# PCIE0_CORE_DBN_CFG_PCIE_CORE register map
Vendor: Texas Instruments
Registers are 32-bit, read-write, reset 0x0 unless marked. A register's access mark holds for its fields unless they carry their own. Offsets are as the file gives them; [hi:lo] are bit positions; {n}, {i} and the like mark numbered series.

## PCIE0_CORE_DBN_CFG_PCIE_CORE (part 3 of 6)
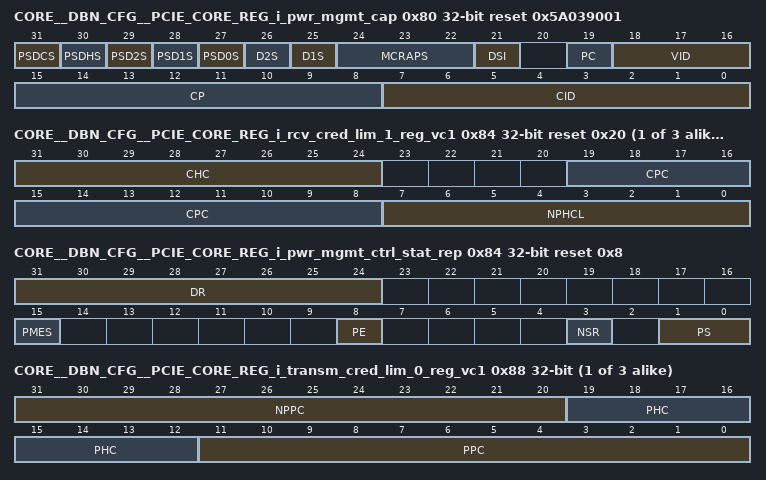
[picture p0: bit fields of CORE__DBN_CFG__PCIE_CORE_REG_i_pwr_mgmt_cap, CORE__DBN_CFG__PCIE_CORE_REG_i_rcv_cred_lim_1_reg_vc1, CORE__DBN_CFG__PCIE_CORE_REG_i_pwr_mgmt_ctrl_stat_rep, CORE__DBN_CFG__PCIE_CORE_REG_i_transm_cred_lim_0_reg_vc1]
0x80 CORE__DBN_CFG__PCIE_CORE_REG_i_pwr_mgmt_cap ro reset 0x5A039001
  [31] PSDCS — Indicates whether the Function is capable of sending PME messages when in the D3cold state. This field can be written from the APB bus by setting [21] bit high of the pcie_mgmt_APB_ADDR during a local management register write.
  [30] PSDHS — Indicates whether the Function is capable of sending PME messages when in the D3hot state. This field can be written from the APB bus by setting [21] bit high of the pcie_mgmt_APB_ADDR during a local management register write.
  [29] PSD2S — Indicates whether the Function is capable of sending PME messages when in the D2 state. This bit is hardwired to 0 because D2 state is not supported.
  [28] PSD1S — Indicates whether the Function is capable of sending PME messages when in the D1 state. This bit is set to 1 by default, but can be modified from the local management bus by writing into Function 0. All other Functions assume the value set in Function 0s Power Management Capabilities Register.
  [27] PSD0S — Indicates whether the Function is capable of sending PME messages when in the D0 state. This field can be written from the APB bus by setting [21] bit high of the pcie_mgmt_APB_ADDR during a local management register write.
  [26] D2S — Set if the Function supports the D2 power state. Currently hardwired to 0.
  [25] D1S — Set if the Function supports the D1 power state. This field can be written from the APB bus by setting [21] bit high of the pcie_mgmt_APB_ADDR during a local management register write.
  [24:22] MCRAPS — Specifies the maximum current drawn by the device from the aux power source in the D3cold state. This field is not implemented in devices not supporting PME notification when in the D3cold state, and is therefore hardwired to 0.
  [21] DSI — This bit, when set, indicates that the device requires additional configuration steps beyond setting up its PCI configuration space, to bring it to the D0 active state from the D0 uninitialized state. This bit is hardwired to 0.
  [19] PC — Not applicable to PCI Express. This bit is hardwired to 0.
  [18:16] VID — Indicates the version of the PCI Bus Power Management Specifications that the Function implements. This field is set by default to 011 [Version 1.2]. This field can be written from the APB bus by setting [21] bit high of the pcie_mgmt_APB_ADDR during a local management register write.
  [15:8] CP — Contains pointer to the next PCI Capability Structure. The Controller sets it to the value defined in the RTL file reg_defaults.h. This field can be written from the APB bus by setting [21] bit high of the pcie_mgmt_APB_ADDR during a local management register write.
  [7:0] CID — Identifies that the capability structure is for Power Management. This field is set by default to 01 hex. This field can be written from the APB bus by setting [21] bit high of the pcie_mgmt_APB_ADDR during a local management register write.
{0x74+0x10*i} CORE__DBN_CFG__PCIE_CORE_REG_i_rcv_cred_lim_1_reg_vc{i} reset 0x20 (i=1..3)
  [31:24] CHC — Completion header credit limit advertised by the Controller for VC {i} [in number of packets]. This field is in units of 1, 4 or 16 Packet Headers based on the Local Posted Header Credit Scale for VC {i}. 00b => [units of 1 Packet Header] 01b => [units of 1 Packet Header] 10b => [units of 4 Packet Headers] 11b => [units of 16 Packet Headers] Note: When Scaled FLow Control is Activated, the programmed credit value is advertised in the InitFC DLLPs. Else, the programmed credit value is internally normalized to units of [1 Packet Header] and then advertised in the InitFC DLLPs. Note: Packet Header represents one maximum-size TLP Header + TLP Digest + maximum number of EndEnd TLP Prefixes permitted in a TLP. Caution: The programmed Header and Payload credit values must not exceed the actual size of the Receive Buffer.
  [19:8] CPC — Completion payload credit limit advertised by the Controller for VC {i} . This field is in units of 4 DWords, 16 DWords or 64 DWords based on the Local Posted Payload Credit Scale for VC {i}. 00b => [units of 4 DWords] 01b => [units of 4 DWords] 10b => [units of 16 DWords] 11b => [units of 64 DWords] Note: When Scaled FLow Control is Activated, the programmed credit value is advertised in the InitFC DLLPs. Else, the programmed credit value is internally normalized to units of 4 DW and then advertised in the InitFC DLLPs. Caution: The programmed Header and Payload credit values must not exceed the actual size of the Receive Buffer.
  [7:0] NPHCL — Non-Posted header credit limit advertised by the Controller for VC {i} [in number of packets]. This field is in units of 1, 4 or 16 Packet Headers based on the Local Posted Header Credit Scale for VC {i}. 00b => [units of 1 Packet Header] 01b => [units of 1 Packet Header] 10b => [units of 4 Packet Headers] 11b => [units of 16 Packet Headers] Note: When Scaled FLow Control is Activated, the programmed credit value is advertised in the InitFC DLLPs. Else, the programmed credit value is internally normalized to units of [1 Packet Header] and then advertised in the InitFC DLLPs. Note: Packet Header represents one maximum-size TLP Header + TLP Digest + maximum number of EndEnd TLP Prefixes permitted in a TLP. Caution: The programmed Header and Payload credit values must not exceed the actual size of the Receive Buffer.
0x84 CORE__DBN_CFG__PCIE_CORE_REG_i_pwr_mgmt_ctrl_stat_rep access not given reset 0x8
  [31:24] DR ro — This optional register is not implemented in the Cadence PCIe Controller. This field is hardwired to 0.
  [15] PMES — This field can be written from the APB bus by setting [21] bit high of the pcie_mgmt_APB_ADDR during a local management register write.. (access R/W1TC)
  [8] PE rw — This bit can be set or cleared from the local management APB bus, by writing a 1 or 0, respectively.
  [3] NSR ro — This bit is set to 1 by default. This field can be written from the APB bus by setting [21] bit high of the pcie_mgmt_APB_ADDR during a local management register write.
  [1:0] PS rw — This field can also be read or written from the local management APBbus.
{0x78+0x10*i} CORE__DBN_CFG__PCIE_CORE_REG_i_transm_cred_lim_0_reg_vc{i} ro (i=1..3)
  [31:20] NPPC — Non-Posted payload credit limit received by the Controller for Link 0 . This field is in units of 4 DWords, 16 DWords or 64 DWords based on the Remote Posted Payload Credit Scale for VC {i}. 00b => [units of 4 DWords] 01b => [units of 4 DWords] 10b => [units of 16 DWords] 11b => [units of 64 DWords]
  [19:12] PHC — Posted header credit limit received by the Controller for this link . This field is in units of 1, 4 or 16 Packet Headers based on the Remote Posted Header Credit Scale for VC {i}. 00b => [units of 1 Packet Header] 01b => [units of 1 Packet Header] 10b => [units of 4 Packet Headers] 11b => [units of 16 Packet Headers] Note: Packet Header represents one maximum-size TLP Header + TLP Digest + maximum number of EndEnd TLP Prefixes permitted in a TLP.
  [11:0] PPC — Posted payload credit limit received by the Controller for this link . This field is in units of 4 DWords, 16 DWords or 64 DWords based on the Remote Posted Payload Credit Scale for VC {i}. 00b => [units of 4 DWords] 01b => [units of 4 DWords] 10b => [units of 16 DWords] 11b => [units of 64 DWords]
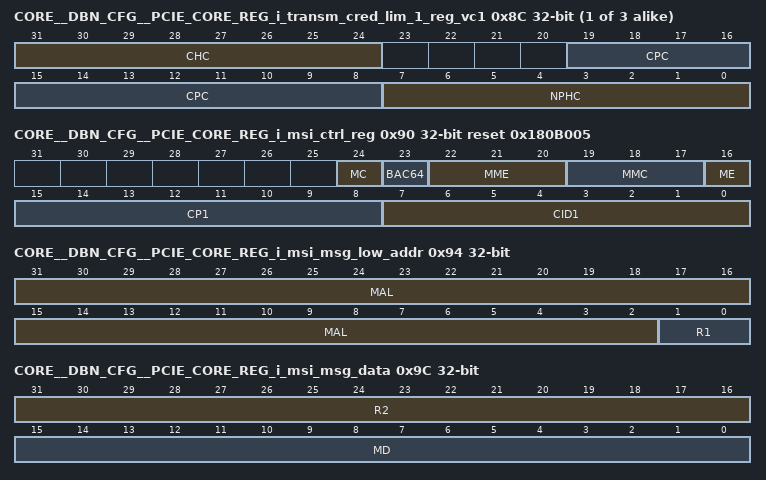
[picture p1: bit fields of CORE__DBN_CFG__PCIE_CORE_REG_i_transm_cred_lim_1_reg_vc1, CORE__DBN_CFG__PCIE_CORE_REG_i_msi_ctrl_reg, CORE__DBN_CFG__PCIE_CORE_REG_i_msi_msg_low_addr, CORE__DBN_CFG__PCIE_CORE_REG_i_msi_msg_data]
{0x7C+0x10*i} CORE__DBN_CFG__PCIE_CORE_REG_i_transm_cred_lim_1_reg_vc{i} ro (i=1..3)
  [31:24] CHC — Completion header credit limit received by the Controller for VC {i} . This field is in units of 1, 4 or 16 Packet Headers based on the Remote Posted Header Credit Scale for VC {i}. 00b => [units of 1 Packet Header] 01b => [units of 1 Packet Header] 10b => [units of 4 Packet Headers] 11b => [units of 16 Packet Headers] Note: Packet Header represents one maximum-size TLP Header + TLP Digest + maximum number of EndEnd TLP Prefixes permitted in a TLP.
  [19:8] CPC — Completion payload credit limit received by the Controller for VC {i} . This field is in units of 4 DWords, 16 DWords or 64 DWords based on the Remote Posted Payload Credit Scale for VC {i}. 00b => [units of 4 DWords] 01b => [units of 4 DWords] 10b => [units of 16 DWords] 11b => [units of 64 DWords]
  [7:0] NPHC — Non-Posted header credit limit received by the Controller for VC {i} . This field is in units of 1, 4 or 16 Packet Headers based on the Remote Posted Header Credit Scale for VC {i}. 00b => [units of 1 Packet Header] 01b => [units of 1 Packet Header] 10b => [units of 4 Packet Headers] 11b => [units of 16 Packet Headers] Note: Packet Header represents one maximum-size TLP Header + TLP Digest + maximum number of EndEnd TLP Prefixes permitted in a TLP.
0x90 CORE__DBN_CFG__PCIE_CORE_REG_i_msi_ctrl_reg access per field reset 0x180B005
  [24] MC ro — can be modified using localmanagement interface
  [23] BAC64 ro — Set to 1 to indicate that the device is capable of generating 64-bit addresses for MSI messages.Can be modified using local management interface
  [22:20] MME rw — Encodes the number of distinct messages that the Controller is programmed to generate for this Function [000 = 1, 001 = 2, 010 = 4, 011 = 8, 100 = 16, 101 = 32]. This setting must be based on the number of interrupt inputs of the Controller that are actually used by this Function. This field can be written from the local management bus.
  [19:17] MMC ro — Encodes the number of distinct messages that the Controller is capable of generating for this Function [000 = 1, 001 = 2, 010 = 4, 011 = 8, 100 = 16, 101 = 32]. Thus, this field defines the number of the interrupt vectors for this Function. The Controller allows up to 32 distinct messages, but the setting of this field must be based on the number of interrupt inputs of the Controller that are actually used by the client. For example, if the client logic uses 8 of the 32 distinct MSI interrupt inputs of the Controller for this Function, then the value of this field must be set to 011. This field can be written from the local management bus. Please see the define den_db_Fx_MSI_MULTIPLE_MSG_CAPABLE values [where x is the function number] for default values of each function in the reg_defaults.v files.
  [16] ME rw — Set by the configuration program to enable the MSI feature. This field can also be written from the local management bus.
  [15:8] CP1 ro — Pointer to the next PCI Capability Structure. This can be modified from the local management bus. This field can be written from the local management bus.
  [7:0] CID1 ro — Specifies that the capability structure is for MSI. Hardwired to 05 hex.
0x94 CORE__DBN_CFG__PCIE_CORE_REG_i_msi_msg_low_addr access per field
  [31:2] MAL rw — Lower bits of the address to be used in MSI messages. This field can also be written from the local management bus.
  [1:0] R1 ro — The two lower bits of the address are hardwired to 0 to align the address on a double-word boundary.
0x98 CORE__DBN_CFG__PCIE_CORE_REG_i_msi_msg_hi_addr
  [31:0] MAH — Contains bits 63:32 of the 64-bit address to be used in MSI Messages. A value of 0 specifies that 32-bit addresses are to be used in the messages. This field can also be written from the local management bus.
0x9C CORE__DBN_CFG__PCIE_CORE_REG_i_msi_msg_data access per field
  [31:16] R2 ro — Hardwired to 0
  [15:0] MD rw — Message data to be used for this Function. This field can also be written from the local management bus.
0xA0 CORE__DBN_CFG__PCIE_CORE_REG_i_msi_mask
  [0] MM — Mask bits for MSI interrupts. The Multiple Message Capable field of the MSI Control Register specifies the number of distinct interrupts for the Function, which determines the number of valid mask bits.
0xA4 CORE__DBN_CFG__PCIE_CORE_REG_i_msi_pending_bits ro
  [0] MP — Pending bits for MSI interrupts. This field can be written from the APB interface to refelct the current pending status.
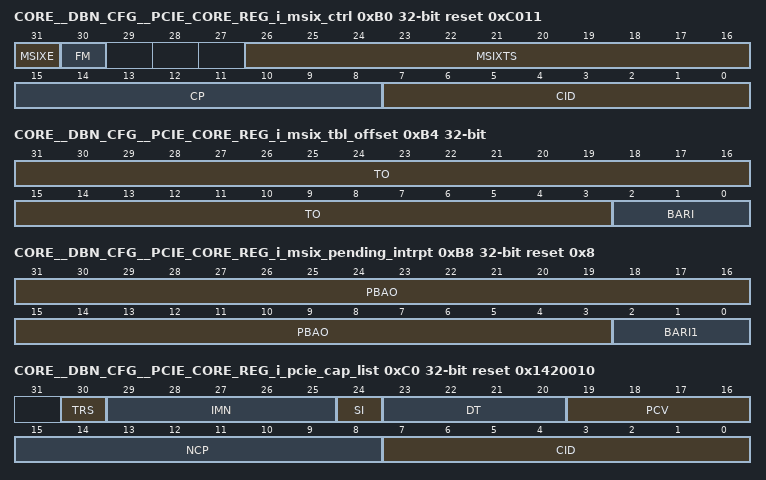
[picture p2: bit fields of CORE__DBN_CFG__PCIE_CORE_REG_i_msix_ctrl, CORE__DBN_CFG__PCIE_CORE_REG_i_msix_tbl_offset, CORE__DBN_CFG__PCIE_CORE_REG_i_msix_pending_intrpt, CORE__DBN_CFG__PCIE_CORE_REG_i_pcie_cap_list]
0xB0 CORE__DBN_CFG__PCIE_CORE_REG_i_msix_ctrl access per field reset 0xC011
  [31] MSIXE rw — Set by the configuration program to enable the MSI-X feature. This field can also be written from the local management bus.
  [30] FM rw — This bit serves as a global mask to all the interrupt conditions associated with this Function. When this bit is set, the Controller will not send out MSI-X messages from this Function. This field can also be written from the local management bus.
  [26:16] MSIXTS ro — Specifies the size of the MSI-X Table, that is, the number of interrupt vectors defined for the Function. The programmed value is 1 minus the size of the table [that is, this field is set to 0 if the table size is 1.]. It can be re-written independently for each Function from the local management bus. Please see the define den_db_Fx_MSIX_TABLE_SIZE values [where x is the function number] for default values of each function in the reg_defaults.v files.
  [15:8] CP ro — Contains pointer to the next PCI Capability Structure. This is set to point to the PCI Express Capability Structure at 30 hex. This can be rewritten independently for each Function from the local management bus.
  [7:0] CID ro — Identifies that the capability structure is for MSI-X. This field is set by default to 11 hex. It can be rewritten independently for each Function from the local management bus.
0xB4 CORE__DBN_CFG__PCIE_CORE_REG_i_msix_tbl_offset ro
  [31:3] TO — Offset of the memory address where the MSI-X Table is located, relative to the selected BAR. The three least significant bits of the address are omitted, as the addresses are QWORD aligned. Please see the define den_db_Fx_MSIX_TABLE_OFFSET values [where x is the function number] for default values of each function in the reg_defaults.v files.
  [2:0] BARI — Identifies the BAR corresponding to the memory address range where the MSI-X Table is located [000 = BAR 0, 001 = BAR 1, ... , 101 = BAR 5]. Please see the define den_db_Fx_MSIX_TABLE_BIR values [where x is the function number] for default values of each function in the reg_defaults.v files.
0xB8 CORE__DBN_CFG__PCIE_CORE_REG_i_msix_pending_intrpt ro reset 0x8
  [31:3] PBAO — Offset of the memory address where the PBA is located, relative to the selected BAR. The three least significant bits of the address are omitted, as the addresses are QWORD aligned. Please see the define den_db_Fx_MSIX_PBA_OFFSET values [where x is the function number] for default values of each function in the reg_defaults.v files.
  [2:0] BARI1 — Identifies the BAR corresponding to the memory address range where the PBA Structure is located [000 = BAR 0, 001 = BAR 1, ... , 101 = BAR 5]. The value programmed must be the same as the BAR Indicator configured in the MSI-X Table Offset Register.Identifies the BAR corresponding to the memory address range where the PBA Structure is located [000 = BAR 0, 001 = BAR 1, ... , 101 = BAR 5]. The value programmed must be the same as the BAR Indicator configured in the MSI-X Table Offset Register. Please see the define den_db_Fx_MSIX_PBA_BIR values [where x is the function number] for default values of each function in the reg_defaults.v files.
0xC0 CORE__DBN_CFG__PCIE_CORE_REG_i_pcie_cap_list ro reset 0x1420010
  [30] TRS — When set to 1, this bit indicates that the device supports routing of Trusted Configuration Requests. Not valid for Endpoints. Hardwired to 0.
  [29:25] IMN — Identifies the MSI or MSI-X interrupt vector for the interrupt message generated corresponding to the status bits in the Slot Status Register, Root Status Register, or this capability structure. This field must be defined based on the chosen interrupt mode - MSI or MSI-X. This field is hardwired to 0.
  [24] SI — When Set, this bit indicates that the Link associated with this Port is connected to a slot
  [23:20] DT — Indicates the type of device implementing this Function. This field is hardwired to 4 in the RP mode.
  [19:16] PCV — Identifies the version number of the capability structure. This field is set to 2 by default to indicate that the Controller is compatible to PCI Express Base Specification Revision 3.0. Can be modified using local management interface after asserting input signal MGMT_TYPE1_CONFIG_REG_ACCESS high.
  [15:8] NCP — Points to the next PCI capability structure. Set to 0 because this is the last capability structure.
  [7:0] CID — Specifies Capability ID assigned by PCI SIG for this structure. This field is hardwired to 10 hex.
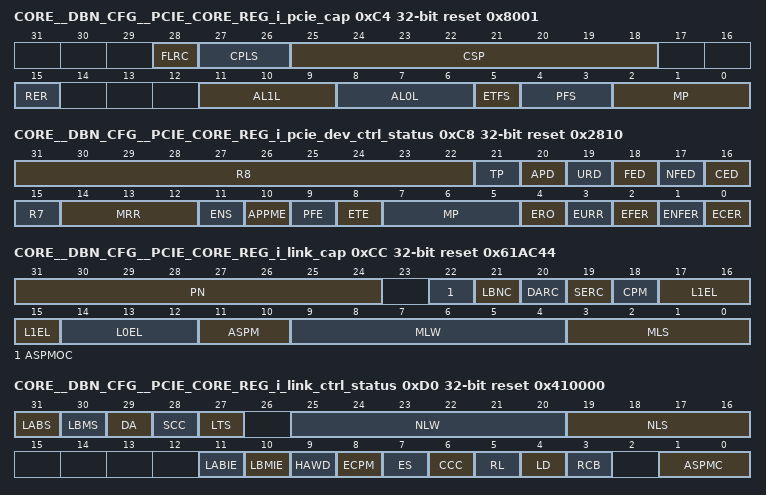
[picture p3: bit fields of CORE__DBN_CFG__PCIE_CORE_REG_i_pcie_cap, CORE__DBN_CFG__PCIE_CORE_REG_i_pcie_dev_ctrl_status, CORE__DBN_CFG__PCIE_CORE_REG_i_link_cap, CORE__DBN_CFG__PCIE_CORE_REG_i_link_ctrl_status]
0xC4 CORE__DBN_CFG__PCIE_CORE_REG_i_pcie_cap ro reset 0x8001
  [28] FLRC — A value of 1b indicates the Function supports the optional Function Level Reset mechanism
  [27:26] CPLS — Specifies the scale used by Slot Power Limit Value. This field can be written from the APB bus by setting [21] bit high of the pcie_mgmt_APB_ADDR during a local management register write. .
  [25:18] CSP — Specifies upper limit on power supplied by slot. This field can be written from the APB bus by setting [21] bit high of the pcie_mgmt_APB_ADDR during a local management register write. .
  [15] RER — Enables role-based errer reporting. This field can be written from the APB bus by setting [21] bit high of the pcie_mgmt_APB_ADDR during a local management register write.
  [11:9] AL1L — Specifies acceptable latency that the Endpoint can tolerate while transitioning from L1 to L0. This field can be written from the APB bus by setting [21] bit high of the pcie_mgmt_APB_ADDR during a local management register write.
  [8:6] AL0L — Specifies acceptable latency that the Endpoint can tolerate while transitioning from L0S to L0. This field can be written from the APB bus by setting [21] bit high of the pcie_mgmt_APB_ADDR during a local management register write.
  [5] ETFS — hard coded to zero .
  [4:3] PFS — This field is used to extend the tag field by combining unused Function bits with the tag bits. This field is hardwired to 00 to disable this feature.
  [2:0] MP — Specifies maximum payload size supported by the device. This field can be written from the APB bus by setting [21] bit high of the pcie_mgmt_APB_ADDR during a local management register write.
0xC8 CORE__DBN_CFG__PCIE_CORE_REG_i_pcie_dev_ctrl_status access not given reset 0x2810
  [31:22] R8 ro
  [21] TP ro — Indicates if any of the Non-Posted requests issued by the RC are still pending.
  [20] APD ro — Set when auxiliary power is detected by the device. This is an unused field.
  [19] URD — Set to 1 by the Controller when it receives an unsupported request. (access R/W1TC)
  [18] FED — Set to 1 by the Controller when it detects a fatal error, regardless of whether the error is masked. (access R/W1TC)
  [17] NFED — Set to 1 by the Controller when it detects a non-fatal error, regardless of whether the error is masked. (access R/W1TC)
  [16] CED — Set to 1 by the Controller when it detects a correctable error, regardless of whether the error is masked. (access R/W1TC)
  [15] R7 ro — Hardwired to 0.
  [14:12] MRR rw — Specifies the maximum size allowed in read requests generated by the device.
  [11] ENS rw — If this bit is Set, the Function is permitted to Set the No Snoop bit in the Requester Attributes of transactions it initiates that do not require hardware enforced cache coherency.
  [10] APPME ro — Hardwired to 0
  [9] PFE ro — Hardwired to 0
  [8] ETE ro — extended tag not enabled. Hence hard coded to zero .
  [7:5] MP rw — Specifies the maximum TLP payload size configured. The device must be able to receive a TLP of this maximum size, and should not generate TLP's larger than this value. Software must set this field based on the maximum payload size in the Device Capabilities Register, and the capability of the other side.
  [4] ERO rw — When set, this bit indicates that the device is allowed to set the Relaxed Ordering bit in the Attributes field of transactions initiated from it., when the transactions do not require Strong Ordering.
  [3] EURR rw — This bit is used to gate the CORRECTABLE_ERROR_OUT, NON_FATAL_ERROR_OUT, FATAL_ERROR_OUT output in Root Port mode on receiving unsupported requests. Note: Alternately, the SERR Enable bit in the Command Register can also be set to enable assertion of FATAL_ERROR_OUT on receiving uncorrectable unsupported requests.
  [2] EFER rw — This bit is used to gate the FATAL_ERROR_OUT output of the Controller in Root Port mode. When an Uncorrectable, Unmasked Error with Uncorrectable Error Severity set to 1 is detected Internally or when a ERR_FATAL message is received by the Controller, in Root Port mode, this bit gates the assertion of FATAL_ERROR_OUT output. Note: Alternately, the SERR Enable bit in the Command Register can also be set to enable assertion of FATAL_ERROR_OUT.
  [1] ENFER rw — This bit is used to gate the NON_FATAL_ERROR_OUT output of the Controller in Root Port mode. When an Uncorrectable, Unmasked Error with Uncorrectable Error Severity set to 0 is detected Internally or when a ERR_NON_FATAL message is received by the Controller, in Root Port mode, this bit gates the assertion of NON_FATAL_ERROR_OUT output. Note: Alternately, the SERR Enable bit in the Command Register can also be set to enable assertion of NON_FATAL_ERROR_OUT.
  [0] ECER rw — This bit is used to gate the CORRECTABLE_ERROR_OUT output of the Controller in Root Port mode. When a Correctable and Unmasked Error is detected Internally or when a ERR_CORR message is received by the Controller, in Root Port mode, this bit gates the assertion of CORRECTABLE_ERROR_OUT output.
0xCC CORE__DBN_CFG__PCIE_CORE_REG_i_link_cap ro reset 0x61AC44
  [31:24] PN — Specifies the port number assigned to the PCI Express link connected to this device. This field can be written from the APB bus by setting [21] bit high of the pcie_mgmt_APB_ADDR during a local management register write.
  [22] ASPMOC — A 1 in this position indicates the device supports the ASPM Optionality feature. This field can be written from the APB bus by setting [21] bit high of the pcie_mgmt_APB_ADDR during a local management register write.
  [21] LBNC — A value of 1b indicates support for the Link Bandwidth Notification status and interrupt mechanisms. This field can be written from the APB bus by setting [21] bit high of the pcie_mgmt_APB_ADDR during a local management register write.
  [20] DARC — Set to 1 if the device is capable of reporting that the DL Control and Management State Machine has reached the DL_Active state. This bit is hardwired to 0, as this version of the Controller does not support the feature.
  [19] SERC — Indicates the capability of the device to report a Surprise Down error condition. This bit is hardwired to 0, as this version of the Controller does not support the feature.
  [18] CPM — Indicates that the device supports removal of reference clocks. Not supported in this version of the Controller. Hardwired to 0.
  [17:15] L1EL — Specifies the exit latency from L1 state. This parameter is dependent on the Physical Layer implementation. This field can be written from the APB bus by setting [21] bit high of the pcie_mgmt_APB_ADDR during a local management register write.
  [14:12] L0EL — Specifies the time required for the device to transition from L0S to L0. This parameter is dependent on the Physical Layer implementation. This field can be written from the APB bus by setting [21] bit high of the pcie_mgmt_APB_ADDR during a local management register write.
  [11:10] ASPM — Indicates the level of ASPM support provided by the device. This field can be written from the APB bus by setting [21] bit high of the pcie_mgmt_APB_ADDR during a local management register write.
  [9:4] MLW — Indicates the maximum number of lanes supported by the device. This field is hardwired based on the setting of the LANE_COUNT_IN strap input.
  [3:0] MLS — Indicates the speeds supported by the link [2.5 GT/s , 5 GT/s , 8 GT/s , 16 GT/s per lane]. This field is hardwired to 0001 [2.5GT/s] when the strap input PCIE_GENERATION_SEL is set to 0, to 0010 [5 GT/s] when the strap is set to 1 , and to 0011 [8 GT/s] when the strap input is set to 10 , and to 0100 [16 GT/s] when the strap input is set to 11 .
0xD0 CORE__DBN_CFG__PCIE_CORE_REG_i_link_ctrl_status access not given reset 0x410000
  [31] LABS — This bit is Set by hardware to indicate that hardware has autonomously changed Link speed or width, without the Port transitioning through DL_Down status, for reasons other than to attempt to correct unreliable Link operation. This triggers an interrupt to be generated through PHY_INTERRUPT_OUT if enabled. Hardwired to 0 if Link Bandwidth Notification Capability is 0. (access R/W1TC)
  [30] LBMS — This bit is Set by hardware to indicate that either link training has completed following write to retrain link bit, or when HW has changed link speed or width to attempt to correct unreliable link operation. This triggers an interrupt to be generated through PHY_INTERRUPT_OUT if enabled. Hardwired to 0 if Link Bandwidth Notification Capability is 0. (access R/W1TC)
  [29] DA ro — Indicates the status of the Data Link Layer. Set to 1 when the DL Control and Management State Machine has reached the DL_Active state. This bit is hardwired to 0 in this version of the Controller.
  [28] SCC ro — Indicates that the device uses the reference clock provided by the connector. This field can be written from the APB bus by setting [21] bit high of the pcie_mgmt_APB_ADDR during a local management register write.
  [27] LTS ro — This bit is set to 1 when the LTSSM is in the Recovery or Configuration states, or if a 1 has been written to the Retrain Link bit but the link training has not yet begun.
  [25:20] NLW ro — Set at the end of link training to the actual link width negotiated between the two sides.
  [19:16] NLS ro — Negotiated link speed of the device. The only supported speed ids are 2.5 GT/s per lane [0001],5 GT/s per lane [0010] ,8 GT/s per lane [0011],16 GT/s per lane [0100].
  [11] LABIE rw — When Set, this bit enables the generation of an interrupt to indicate that the Link Autonomous Bandwidth Status bit has been Set. This enables an interrupt to be generated through PHY_INTERRUPT_OUT if triggered. Hardwired to 0 if Link Bandwidth Notification Capability is 0.
  [10] LBMIE rw — When Set, this bit enables the generation of an interrupt to indicate that the Link Bandwidth Management Status bit has been Set. This enables an interrupt to be generated through PHY_INTERRUPT_OUT if triggered. Hardwired to 0 if Link Bandwidth Notification Capability is 0.
  [9] HAWD rw — When this bit is set, the local application must not request to change the operating width of the link, other than attempting to correct unreliable Link operation by reducing Link width.
  [8] ECPM ro — This field is hardwired to 0 when the Controller is in the RC mode.
  [7] ES rw — Set to 1 to extend the sequence of ordered sets transmitted while exiting from the L0S state.
  [6] CCC rw — A value of 0 indicates that the reference clock of this device is asynchronous to that of the upstream device. A value of 1 indicates that the reference clock is common.
  [5] RL ro — Setting this bit to 1 causes the LTSSM to initiate link training. This bit always reads as 0. This bit can be set by Host SW at any time independent of the LTSSM state. If the LTSSM is not in L0 state, the Controller will internally register the retrain command and initiate the link retrain immediately after the LTSSM reaches L0. For example, if the LTSSM is already in Recovery, the Controller will initiate Retrain Link after the LTSSM transitions back to L0 state.
  [4] LD rw — Writing a 1 to this bit position causes the LTSSM to go to the Disable Link state. The LTSSM stays in the Disable Link state while this bit is set.
  [3] RCB ro — Indicates the Read Completion Boundary of the Root Port [0 = 64 bytes, 1 = 128 bytes]. This field can be written from the APB bus by setting [21] bit high of the pcie_mgmt_APB_ADDR during a local management register write.
  [1:0] ASPMC rw — Controls the level of ASPM support on the PCI Express link associated with the function. The valid setting are 00: ASPM disabled 01: L0s entry enabled, L1 disabled 10: L1 entry enabled, L0s disabled 11: Both L0s and L1 enabled. Note that the ASPM Control bits can be enabled only if the corresponding ASPM Support[1:0] bit is 1 in the Link Capabilities Register.
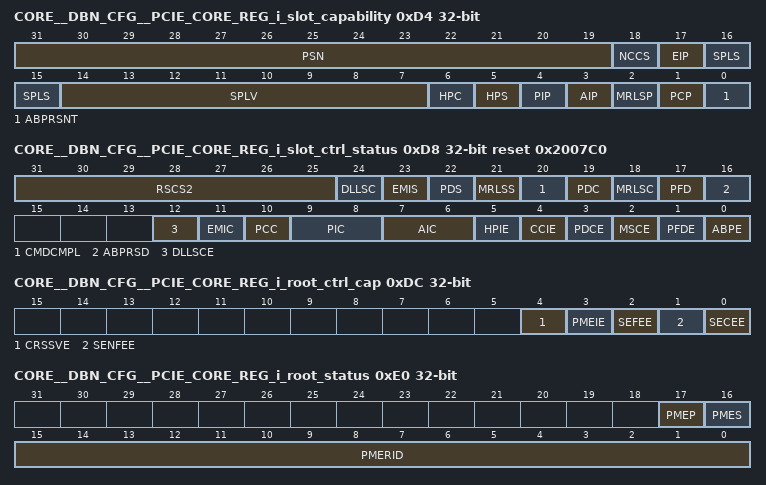
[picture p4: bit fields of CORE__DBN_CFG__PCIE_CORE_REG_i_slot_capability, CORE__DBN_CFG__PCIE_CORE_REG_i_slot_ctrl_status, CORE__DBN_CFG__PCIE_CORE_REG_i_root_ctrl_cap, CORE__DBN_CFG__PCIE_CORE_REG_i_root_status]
0xD4 CORE__DBN_CFG__PCIE_CORE_REG_i_slot_capability ro
  [31:19] PSN — This field indicates the physical slot number attached to this Port. This field must be hardware initialized to a value that assigns a slot number that is unique within the chassis, regardless of the form factor associated with the slot. This field must be initialized to zero for Ports connected to devices that are either integrated on the system board or integrated within the same silicon as the Switch device or Root Port.
  [18] NCCS — When Set, this bit indicates that this slot does not generate software notification when an issued command is completed by the Hot-Plug Controller. This bit is only permitted to be Set if the hot-plug capable Port is able to accept writes to all fields of the Slot Control register without delay between successive writes.
  [17] EIP — When Set, this bit indicates that an Electromechanical Interlock is implemented on the chassis for this slot.
  [16:15] SPLS — Specifies the scale used for the Slot Power Limit Value . Range of Values: 00b = 1.0x 01b = 0.1x 10b = 0.01x 11b = 0.001x This register must be implemented if the Slot Implemented bit is Set. Writes to this register also cause the Port to send the Set_Slot_Power_Limit Message. The default value prior to hardware/firmware initialization is 00b.
  [14:7] SPLV — In combination with the Slot Power Limit Scale value, specifies the upper limit on power supplied by the slot [see Section 6.9] or by other means to the adapter. Power limit [in Watts] is calculated by multiplying the value in this field by the value in the Slot Power Limit Scale field except when the Slot Power Limit Scale field equals 00b [1.0x] and Slot Power Limit Value exceeds EFh, the following alternative encodings are used: F0h = 250 W Slot Power Limit F1h = 275 W Slot Power Limit F2h = 300 W Slot Power Limit F3h to FFh = Reserved for Slot Power Limit values above 300 W This register must be implemented if the Slot Implemented bit is Set. Writes to this register also cause the Port to send the Set_Slot_Power_Limit Message. The default value prior to hardware/firmware initialization is 0000 0000b.
  [6] HPC — When Set, this bit indicates that this slot is capable of supporting hot-plug operations.
  [5] HPS — When Set, this bit indicates that an adapter present in this slot might be removed from the system without any prior notification. This is a form factor specific capability. This bit is an indication to the operating system to allow for such removal without impacting continued software operation.
  [4] PIP — When Set, this bit indicates that a Power Indicator is electrically controlled by the chassis for this slot.
  [3] AIP — When Set, this bit indicates that an Attention Indicator is electrically controlled by the chassis.
  [2] MRLSP — When Set, this bit indicates that an MRL Sensor is implemented on the chassis for this slot.
  [1] PCP — When Set, this bit indicates that a software programmable Power Controller is implemented for this slot/adapter [depending on form factor].
  [0] ABPRSNT — When Set, this bit indicates that an Attention Button for this slot is electrically controlled by the chassis.
0xD8 CORE__DBN_CFG__PCIE_CORE_REG_i_slot_ctrl_status access not given reset 0x2007C0
  [31:25] RSCS2 ro
  [24] DLLSC — This bit is Set when the value reported in the Data Link Layer Link Active bit of the Link Status register is changed. In response to a Data Link Layer State Changed event, software must read the Data Link Layer Link Active bit of the Link Status register to determine if the Link is active before initiating configuration cycles to the hot plugged device. (access R/W1TC)
  [23] EMIS ro — If an Electromechanical Interlock is implemented, this bit indicates the status of the Electromechanical Interlock. Defined encodings are: 0b Electromechanical Interlock Disengaged 1b Electromechanical Interlock Engaged
  [22] PDS ro — This bit indicates the presence of an adapter in the slot, reflected by the logical 'OR' of the Physical Layer in-band presence detect mechanism and, if present, any out-of-band presence detect mechanism defined for the slot's corresponding form factor. Note that the in-band presence detect mechanism requires that power be applied to an adapter for its presence to be detected. Consequently, form factors that require a power controller for hot-plug must implement a physical pin presence detect mechanism. Defined encodings are: 0b Slot Empty 1b Card Present in slot.
  [21] MRLSS ro — This bit reports the status of the MRL sensor if implemented. Defined encodings are: 0b MRL Closed 1b MRL Open
  [20] CMDCMPL — If Command Completed notification is supported [if the No Command Completed Support bit in the Slot Capabilities register is 0b], this bit is Set when a hot-plug command has completed and the Hot-Plug Controller is ready to accept a subsequent command. The Command Completed status bit is Set as an indication to host software that the Hot- Plug Controller has processed the previous command and is ready to receive the next command; it provides no guarantee that the action corresponding to the command is complete. If Command Completed notification is not supported, this bit must be hardwired to 0b. (access R/W1TC)
  [19] PDC — This bit is set when the value reported in the Presence Detect State bit is changed. (access R/W1TC)
  [18] MRLSC — If an MRL sensor is implemented, this bit is Set when a MRL Sensor state change is detected. If an MRL sensor is not implemented, this bit must not be Set. (access R/W1TC)
  [17] PFD — If a Power Controller that supports power fault detection is implemented, this bit is Set when the Power Controller detects a power fault at this slot. Note that, depending on hardware capability, it is possible that a power fault can be detected at any time, independent of the Power Controller Control setting or the occupancy of the slot. If power fault detection is not supported, this bit must not be Set. (access R/W1TC)
  [16] ABPRSD — If an Attention Button is implemented, this bit is Set when the attention button is pressed. If an Attention Button is not supported, this bit must not be Set. (access R/W1TC)
  [12] DLLSCE rw — If the Data Link Layer Link Active Reporting capability is 1b, this bit enables software notification when Data Link Layer Link Active bit is changed. If the Data Link Layer Link Active Reporting Capable bit is 0b, this bit is permitted to be read-only with a value of 0b. Default value of this bit is 0b.
  [11] EMIC ro — If an Electromechanical Interlock is implemented, a write of 1b to this bit causes the state of the interlock to toggle. A write of 0b to this bit has no effect. A read of this bit always returns a 0b.
  [10] PCC rw — If a Power Controller is implemented, this bit when written sets the power state of the slot per the defined encodings. Reads of this bit must reflect the value from the latest write, even if the corresponding hot-plug command is not complete, unless software issues a write, if required to, without waiting for the previous command to complete in which case the read value is undefined. The defined encodings are: 0b Power On 1b Power Off
  [9:8] PIC rw — If a Power Indicator is implemented, writes to this field set the Power Indicator to the written state. Reads of this field must reflect the value from the latest write,Defined encodings are: 00b Reserved 01b On 10b Blink 11b Off
  [7:6] AIC rw — If an Attention Indicator is implemented, writes to this field set the Attention Indicator to the written state. Reads of this field must reflect the value from the latest write,Defined encodings are: 00b Reserved 01b On 10b Blink 11b Off
  [5] HPIE rw — When Set, this bit enables generation of an interrupt on enabled hot-plug events. If the Hot Plug Capable bit in the Slot Capabilities register is Clear, this bit is permitted to be read-only with a value of 0b. Default value of this bit is 0b.
  [4] CCIE rw — If Command Completed notification is supported [if the No Command Completed Support bit in the Slot Capabilities register is 0b], when Set, this bit enables software notification when a hot-plug command is completed by the Hot-Plug Controller. If Command Completed notification is not supported, this bit must be hardwired to 0b. Default value of this bit is 0b.
  [3] PDCE rw — When Set, this bit enables software notification on a presence detect changed event. If the Hot-Plug Capable bit in the Slot Capabilities register is 0b, this bit is permitted to be read-only with a value of 0b. Default value of this bit is 0b.
  [2] MSCE rw — When Set, this bit enables software notification on a MRL sensor changed event If the MRL Sensor Present bit in the Slot Capabilities register is Clear, this bit is permitted to be read-only with a value of 0b. Default value of this bit is 0b.
  [1] PFDE rw — When Set, this bit enables software notification on a power fault event If a Power Controller that supports power fault detection is not implemented, this bit is permitted to be read-only with a value of 0b. Default value of this bit is 0b.
  [0] ABPE rw — When Set to 1b, this bit enables software notification on an attention button pressed event. If the Attention Button Present bit in the Slot Capabilities register is 0b, this bit is permitted to be read-only with a value of 0b. Default value of this bit is 0b.
0xDC CORE__DBN_CFG__PCIE_CORE_REG_i_root_ctrl_cap access per field
  [4] CRSSVE ro — This capability is not implemented and this bit is hardwired to 0b.
  [3] PMEIE rw — This field can be read and written from the local management APB bus, but its value is not used within the Controller.
  [2] SEFEE rw — This field can be read and written from the local management APB bus, but its value is not used within the Controller.
  [1] SENFEE rw — This field can be read and written from the local management APB bus, but its value is not used within the Controller.
  [0] SECEE rw — This field can be read and written from the local management APB bus, but its value is not used within the Controller.
0xE0 CORE__DBN_CFG__PCIE_CORE_REG_i_root_status access not given
  [17] PMEP ro — This field can be written from the APB bus by setting [21] bit high of the pcie_mgmt_APB_ADDR during a local management register write.
  [16] PMES — This field is not set by the Controller but can be cleared by writing a 1 from the local management APB bus. This field can be written from the APB bus by setting [21] bit high of the pcie_mgmt_APB_ADDR during a local management register write. (access R/W1TC)
  [15:0] PMERID ro — This field can be written from the APB bus by setting [21] bit high of the pcie_mgmt_APB_ADDR during a local management register write.
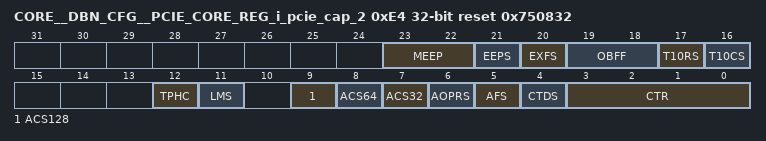
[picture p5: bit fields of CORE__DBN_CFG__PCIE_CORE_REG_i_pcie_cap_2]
0xE4 CORE__DBN_CFG__PCIE_CORE_REG_i_pcie_cap_2 ro reset 0x750832
  [23:22] MEEP — Indicates the maximum number of End-End TLP Prefixes supported by the Function. The supported values are: 01b 1 End-End TLP Prefix 10b 2 End-End TLP Prefixes. This field can be written from the APB bus by setting [21] bit high of the pcie_mgmt_APB_ADDR during a local management register write
  [21] EEPS — Indicates whether the Function supports End-End TLP Prefixes. A 1 in this field indicates that the Function supports receiving TLPs containing End-End TLP Prefixes. This field can be written from the APB bus by setting [21] bit high of the pcie_mgmt_APB_ADDR during a local management register write
  [20] EXFS — Indicates that the Function supports the 3-bit definition of the Fmt field in the TLP header. This bit is hardwired to 1 for all Physical Functions.
  [19:18] OBFF — A 1 in this bit position indicates that the Function supports the Optimized Buffer Flush/Fill [OBFF] capability using message signaling. This field can be written from the APB bus by setting [21] bit high of the pcie_mgmt_APB_ADDR during a local management register write
  [17] T10RS — If set function supports 1-bit requester capability; otherwise, the function does not. This bit can be disabled using local management register.
  [16] T10CS — If set function supports 1-bit completer capability; otherwise, the function does not. This field can be modified using local management interface.
  [12] TPHC — Hardwired to 0.
  [11] LMS — A value of 1b indicates support for the optional Latency Tolerance Reporting [LTR] mechanism. This field can be written from the APB bus by setting [21] bit high of the pcie_mgmt_APB_ADDR during a local management register write.
  [9] ACS128 — Hardwired to 0.
  [8] ACS64 — Hardwired to 0.
  [7] ACS32 — Hardwired to 0.
  [6] AOPRS — Applicable only to Switch Upstream Ports, Switch Downstream Ports, and Root Ports; must be 0b for other Function types. This bit must be set to 1b if the Port supports this optional capability. This field can be written from the APB bus by setting [21] bit high of the pcie_mgmt_APB_ADDR during a local management register write.
  [5] AFS — A 1 in this bit indicates that the device is able to forward TLPs with function number greater than 8. This field can be written from the APB bus by setting [21] bit high of the pcie_mgmt_APB_ADDR during a local management register write.
  [4] CTDS — A 1 in this field indicates that the associated Function supports the capability to turn off its Completion timeout. This field can be written from the APB bus by setting [21] bit high of the pcie_mgmt_APB_ADDR during a local management register write.
  [3:0] CTR — Specifies the Completion Timeout values supported by the device. This field is set by default to 0010 [10 ms - 250 ms], but can be modified from the local management APB bus. The actual timeout values are in two programmable local management registers, which allow the timeout settings of the two sub-ranges within Range B to be programmed independently. This field can be written from the APB bus by setting [21] bit high of the pcie_mgmt_APB_ADDR during a local management register write.
